AUTOSAR XML (schema 4-2-1)
standard types defined: float32, float64, sint8, sint16, sint32, uint8, uint16, uint32, boolean, dtRef_VOID, Float32, Boolean, UInt8
package /FoundationPkg/FoundationArchitecturePkg
  constant specification iAssistTorque_AssistanceTorque_Init: value-spec={short-label=iAssistTorque_AssistanceTorque_Init, fields=[0 Nm, 0]}
  sender receiver interface iAssistTorque
    data AssistanceTorque: sw-calibration-access=READ-ONLY, type=tAssistTorque, init-value=constant-reference=iAssistTorque_AssistanceTorque_Init
  5 x constant specification:
    iColumnData_ColumnTorque_Init: value-spec={short-label=iColumnData_ColumnTorque_Init, fields=[0 Nm, 0 Nm/s, 0]}
    iColumnData_SteeringPositionLower_Init: value-spec={short-label=iColumnData_SteeringPositionLower_Init, fields=[0 deg, 0, {short-label=tColumnPosition_EQf_Init, fields=[1, 1, 1, 1]}]}
    iColumnData_ColumnVelocity_Init: value-spec={short-label=iColumnData_ColumnVelocity_Init, fields=[0 revs/S, 0 revs/S, 0]}
    iColumnData_SteeringPositionUpper_Init: value-spec={short-label=iColumnData_SteeringPositionUpper_Init, fields=[0 deg, 0, {short-label=tColumnPosition_EQf_Init, fields=[1, 1, 1, 1]}]}
    iColumnData_ColumnPositionLower_Init: value-spec={short-label=iColumnData_ColumnPositionLower_Init, fields=[0 deg, 0, {short-label=tColumnPosition_EQf_Init, fields=[1, 1, 1, 1]}]}
  sender receiver interface iColumnData
    5 x data, all with sw-calibration-access=READ-ONLY:
      ColumnTorque: type=tInputTorque, init-value=constant-reference=iColumnData_ColumnTorque_Init
      SteeringPositionLower: type=tColumnPosition, init-value=constant-reference=iColumnData_SteeringPositionLower_Init
      ColumnVelocity: type=tColumnVelocity, init-value=constant-reference=iColumnData_ColumnVelocity_Init
      SteeringPositionUpper: type=tColumnPosition, init-value=constant-reference=iColumnData_SteeringPositionUpper_Init
      ColumnPositionLower: type=tColumnPosition, init-value=constant-reference=iColumnData_ColumnPositionLower_Init
  client server interface iRack
    4 x operation:
      getMaxPhysicalAssist
        arg maxPhysicalAssist: type=Nm, direction=OUT
      initialisationColumnAngle
        arg pinionAngle: type=Degrees, direction=IN
      translateColumnAngleToRackPosition
        arg pinionAngle: type=Degrees, direction=IN
        arg rackPosition: type=mm, direction=OUT
      translateRackPositionToColumnAngle
        arg rackPosition: type=mm, direction=IN
        arg columnAngle: type=Degrees, direction=OUT
  constant specification iVehicleData_VehicleSpeed_Init: value-spec={short-label=iVehicleData_VehicleSpeed_Init, fields=[0 Kph, 0, 0]}
  constant specification iVehicleData_EstimatedSteeringPosition_Init: value-spec={short-label=iVehicleData_EstimatedSteeringPosition_Init, fields=[0 deg, 0, 0 %]}
  constant specification iVehicleData_YawRate_Init: value-spec={short-label=iVehicleData_YawRate_Init, fields=[0 deg/S, 0]}
  sender receiver interface iVehicleData
    data VehicleSpeed: sw-calibration-access=READ-ONLY, type=tVehicleSpd, init-value=constant-reference=iVehicleData_VehicleSpeed_Init
    data EstimatedSteeringPosition: sw-calibration-access=READ-ONLY, type=tEstimatedSteeringPosition, init-value=constant-reference=iVehicleData_EstimatedSteeringPosition_Init
    data YawRate: sw-calibration-access=READ-ONLY, type=tYawRateData, init-value=constant-reference=iVehicleData_YawRate_Init
  constant specification iFitness_ControllerFitness_Init: value-spec=3
  sender receiver interface iFitness
    data ControllerFitness: sw-calibration-access=READ-ONLY, type=tQualityFactor, init-value=constant-reference=iFitness_ControllerFitness_Init
  constant specification iTuneData_VEHICLE_SPEED_BREAKPOINTS_Init: value-spec=[0.0, 5.0, 10.0, 15.0, 25.0, 35.0, 50.0, 70.0, 90.0, 120.0, 150.0, 190.0]
  constant specification iTuneData_NUM_STEERING_TUNES_Init: value-spec=1
  parameter interface iTuneData
    parameter data prototype VEHICLE_SPEED_BREAKPOINTS: category=ARRAY, sw-addr-method=VehicleTune, sw-calibration-access=READ-WRITE, type=tVspdBkpts_0_0_to_255_0, init-value=constant-reference=iTuneData_VEHICLE_SPEED_BREAKPOINTS_Init
    parameter data prototype NUM_STEERING_TUNES: category=VALUE, sw-addr-method=VehicleTune, sw-calibration-access=READ-WRITE, type=UInt8_1_to_10, init-value=constant-reference=iTuneData_NUM_STEERING_TUNES_Init
  client server interface iRackSizing
    operation getMaxRackTravel
      arg maxRackTravel: type=Degrees, direction=OUT
  client server interface iResetResPositions
    operation resetResLeRiPosition
      arg StraightAheadOffSet: type=tStraightAheadOffset, direction=IN
  constant specification iArbitorResponse_ArbitrationState_Init: value-spec=5
  sender receiver interface iArbitorResponse
    data ArbitrationState: sw-calibration-access=READ-ONLY, type=tArbitrationState, init-value=constant-reference=iArbitorResponse_ArbitrationState_Init
  constant specification iArbitatorRequest_ActivationRequest_Init: value-spec=0
  sender receiver interface iArbitatorRequest
    data ActivationRequest: sw-calibration-access=READ-ONLY, type=tArbitrationState, init-value=constant-reference=iArbitatorRequest_ActivationRequest_Init
  constant specification iResPosition_ResPosnInUse_Init: value-spec={short-label=iResPosition_ResPosnInUse_Init, fields=[0 deg, 0 deg]}
  sender receiver interface iResPosition
    data ResPosnInUse: sw-calibration-access=READ-ONLY, type=tResPosnInUse, init-value=constant-reference=iResPosition_ResPosnInUse_Init
  client server interface iResEnableRequest
    operation setRESEnableRequest
      arg Request: type=Boolean, direction=IN
package /FoundationPkg/FoundationArchitecturePkg/FoundationControllerPkg
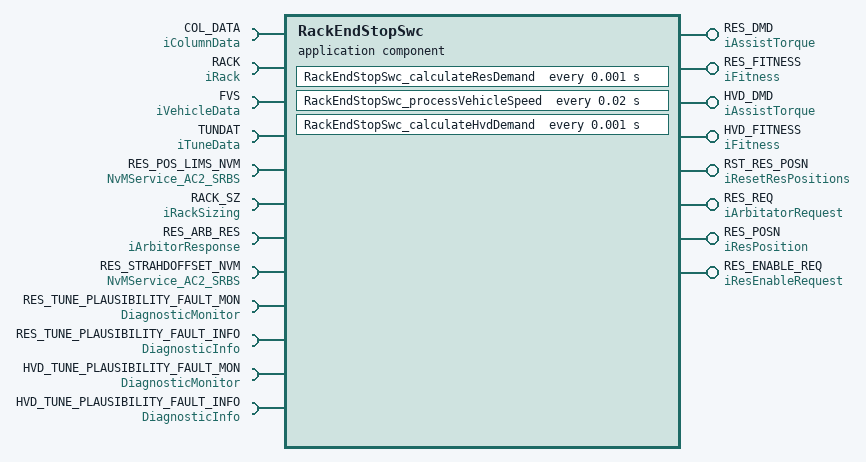
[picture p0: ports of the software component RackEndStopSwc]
  application sw component type RackEndStopSwc
    provide port RES_DMD: nonqueued-sender-com-spec{data-element=AssistanceTorque, init-value=constant-reference=iAssistTorque_AssistanceTorque_Init}, provided-interface=iAssistTorque
    require port COL_DATA: required-interface=iColumnData
      required-com-specs:
        data-element=ColumnTorque, init-value=constant-reference=iColumnData_ColumnTorque_Init
        data-element=SteeringPositionLower, init-value=constant-reference=iColumnData_SteeringPositionLower_Init
        data-element=ColumnVelocity, init-value=constant-reference=iColumnData_ColumnVelocity_Init
        data-element=SteeringPositionUpper, init-value=constant-reference=iColumnData_SteeringPositionUpper_Init
        data-element=ColumnPositionLower, init-value=constant-reference=iColumnData_ColumnPositionLower_Init
    require port RACK: required-interface=iRack
    require port FVS: required-interface=iVehicleData
      required-com-specs:
        data-element=VehicleSpeed, init-value=constant-reference=iVehicleData_VehicleSpeed_Init
        data-element=EstimatedSteeringPosition, init-value=constant-reference=iVehicleData_EstimatedSteeringPosition_Init
        data-element=YawRate, init-value=constant-reference=iVehicleData_YawRate_Init
    provide port RES_FITNESS: nonqueued-sender-com-spec{data-element=ControllerFitness, init-value=constant-reference=iFitness_ControllerFitness_Init}, provided-interface=iFitness
    require port TUNDAT: required-interface=iTuneData
      required-com-specs:
        init-value=constant-reference=iTuneData_VEHICLE_SPEED_BREAKPOINTS_Init, parameter=VEHICLE_SPEED_BREAKPOINTS
        init-value=constant-reference=iTuneData_NUM_STEERING_TUNES_Init, parameter=NUM_STEERING_TUNES
    require port RES_POS_LIMS_NVM: required-interface=NvMService_AC2_SRBS
    provide port HVD_DMD: nonqueued-sender-com-spec{data-element=AssistanceTorque, init-value=constant-reference=iAssistTorque_AssistanceTorque_Init}, provided-interface=iAssistTorque
    provide port HVD_FITNESS: nonqueued-sender-com-spec{data-element=ControllerFitness, init-value=constant-reference=iFitness_ControllerFitness_Init}, provided-interface=iFitness
    require port RACK_SZ: required-interface=iRackSizing
    provide port RST_RES_POSN: server-com-spec{operation=resetResLeRiPosition, queue-length=1}, provided-interface=iResetResPositions
    require port RES_ARB_RES: nonqueued-receiver-com-spec{data-element=ArbitrationState, init-value=constant-reference=iArbitorResponse_ArbitrationState_Init}, required-interface=iArbitorResponse
    provide port RES_REQ: nonqueued-sender-com-spec{data-element=ActivationRequest, init-value=constant-reference=iArbitatorRequest_ActivationRequest_Init}, provided-interface=iArbitatorRequest
    provide port RES_POSN: nonqueued-sender-com-spec{data-element=ResPosnInUse, init-value=constant-reference=iResPosition_ResPosnInUse_Init}, provided-interface=iResPosition
    provide port RES_ENABLE_REQ: server-com-spec{operation=setRESEnableRequest, queue-length=1}, provided-interface=iResEnableRequest
    5 x require port:
      RES_STRAHDOFFSET_NVM: required-interface=NvMService_AC2_SRBS
      RES_TUNE_PLAUSIBILITY_FAULT_MON: required-interface=DiagnosticMonitor
      RES_TUNE_PLAUSIBILITY_FAULT_INFO: required-interface=DiagnosticInfo
      HVD_TUNE_PLAUSIBILITY_FAULT_MON: required-interface=DiagnosticMonitor
      HVD_TUNE_PLAUSIBILITY_FAULT_INFO: required-interface=DiagnosticInfo
    behavior RackEndStopSwc_IB: data-type-mapping=MappingSet, handle-termination-and-restart=NO-SUPPORT
      ar-typed-per-instance-memorys:
        data ResPositionLimitsNvmData: category=STRUCTURE, sw-calibration-access=READ-ONLY, type=tResPositionLimitsNvmData
        data ResStraightAheadOffsetNvmData: category=STRUCTURE, sw-calibration-access=READ-ONLY, type=tResStraightAheadOffsetNvmData
      timing event Event_calculateResDemand: start-on-event=RackEndStopSwc_calculateResDemand, period=0.001
      timing event Event_processVehicleSpeed: start-on-event=RackEndStopSwc_processVehicleSpeed, period=0.02
      init event Event_initialiser_Init: start-on-event=RackEndStopSwc_initialiser
      timing event Event_calculateHvdDemand: start-on-event=RackEndStopSwc_calculateHvdDemand, period=0.001
      operation invoked event Event_resetResLeRiPosition: start-on-event=RackEndStopSwc_resetResLeRiPosition, operation=RST_RES_POSN.resetResLeRiPosition
      operation invoked event Event_setRESEnableRequest: start-on-event=RackEndStopSwc_setRESEnableRequest, operation=RES_ENABLE_REQ.setRESEnableRequest
      explicit-inter-runnable-variables:
        4 x data, all with sw-calibration-access=READ-ONLY:
          triggeringCnt: type=UInt8, init-value=constant-reference=RackEndStopSwc_triggeringCnt_Init
          straightAheadOffset_Value: type=Degrees, init-value=constant-reference=straightAheadOffset_Value_Init
          straightAheadOffset_Qf: type=tQualityFactor, init-value=constant-reference=straightAheadOffset_Qf_Init
          enableResFunctionality: type=Boolean, init-value=constant-reference=RackEndStopSwc_enableResFunctionality_Init  # dedicated to enable/disable the execution of RES functionality
      implicit-inter-runnable-variables:
        9 x data, all with sw-calibration-access=READ-ONLY:
          trqLimit: type=Nm, init-value=constant-reference=RackEndStopSwc_trqLimit_Init
          trqFactor: type=Nm, init-value=constant-reference=RackEndStopSwc_trqFactor_Init
          lwrThres: type=Degrees, init-value=constant-reference=RackEndStopSwc_lwrThres_Init
          denominator: type=Float32, init-value=constant-reference=RackEndStopSwc_denominator_Init
          deadBandLimit: type=Float32, init-value=constant-reference=RackEndStopSwc_deadBandLimit_Init
          linearFactor: type=Float32, init-value=constant-reference=RackEndStopSwc_linearFactor_Init
          maxDampFactor: type=Float32, init-value=constant-reference=RackEndStopSwc_maxDampFactor_Init
          ResTunePlausibilityQf: type=tQualityFactor, init-value=constant-reference=RackEndStopSwc_ResTunePlausibilityQf_Init
          HvdTunePlausibilityQf: type=tQualityFactor, init-value=constant-reference=RackEndStopSwc_HvdTunePlausibilityQf_Init
      per-instance-parameters:
        22 x parameter data prototype:
          RES_POS_OUTWARD_ADAPTION_ENABLED: category=VALUE, sw-addr-method=VehicleTune, sw-calibration-access=READ-WRITE, type=Boolean, init-value=constant-reference=VehicleTune_RES_POS_OUTWARD_ADAPTION_ENABLED_Init
          RES_UPPER_THRESHOLD: category=VALUE, sw-addr-method=VehicleTune, sw-calibration-access=READ-WRITE, type=Degrees_0_0_to_63_0, init-value=constant-reference=VehicleTune_RES_UPPER_THRESHOLD_Init
          RES_VSPD_BKPTS: category=ARRAY, sw-addr-method=VehicleTune, sw-calibration-access=READ-WRITE, type=tResVspdBkpts_0_0_to_255_0, init-value=constant-reference=VehicleTune_RES_VSPD_BKPTS_Init
          RES_LOWER_THRESHOLD_MAP: category=ARRAY, sw-addr-method=VehicleTune, sw-calibration-access=READ-WRITE, type=tResDegreesMap_1_0_to_127_0, init-value=constant-reference=VehicleTune_RES_LOWER_THRESHOLD_MAP_Init
          RES_MAX_TORQUE_FACTOR_MAP: category=ARRAY, sw-addr-method=VehicleTune, sw-calibration-access=READ-WRITE, type=tResPercentMap_0_0_to_1_0, init-value=constant-reference=VehicleTune_RES_MAX_TORQUE_FACTOR_MAP_Init
          RES_TORQUE_LIMIT_MAP: category=ARRAY, sw-addr-method=VehicleTune, sw-calibration-access=READ-WRITE, type=tResPercentMap_0_0_to_1_0, init-value=constant-reference=VehicleTune_RES_TORQUE_LIMIT_MAP_Init
          RES_MAX_OUTWARD_ADAPTATION_THRESHOLD: category=VALUE, sw-addr-method=VehicleTune, sw-calibration-access=READ-WRITE, type=Degrees_0_0_to_720_0, init-value=constant-reference=VehicleTune_RES_MAX_OUTWARD_ADAPTATION_THRESHOLD_Init
          HVD_DEAD_BAND_LIMIT_MAP: category=ARRAY, sw-addr-method=VehicleTune, sw-calibration-access=READ-WRITE, type=tHvdDeadBandLimitMap_2_5_to_8_0, init-value=constant-reference=VehicleTune_HVD_DEAD_BAND_LIMIT_MAP_Init
          HVD_LINEAR_FACTOR_MAP: category=ARRAY, sw-addr-method=VehicleTune, sw-calibration-access=READ-WRITE, type=tHvdLinearFactorMap_0_0_to_2_0, init-value=constant-reference=VehicleTune_HVD_LINEAR_FACTOR_MAP_Init
          HVD_MAX_DAMP_LIMIT_MAP: category=ARRAY, sw-addr-method=VehicleTune, sw-calibration-access=READ-WRITE, type=tHvdMaxDampLimitMap_0_0_to_1_0, init-value=constant-reference=VehicleTune_HVD_MAX_DAMP_LIMIT_MAP_Init  # Column velocity threshold for RES damping
          RES_TOLERANCE_MARGIN: category=VALUE, sw-addr-method=VehicleTune, sw-calibration-access=READ-WRITE, type=Degrees_0_0_to_50_0, init-value=constant-reference=VehicleTune_RES_TOLERANCE_MARGIN_Init
          RES_DEAC_TQ_RAMP_RATE: category=VALUE, sw-addr-method=VehicleTune, sw-calibration-access=READ-WRITE, type=NmPerSec_50_0_to_255000_0, init-value=constant-reference=VehicleTune_RES_DEAC_TQ_RAMP_RATE_Init
          HVD_MIN_COL_V_THD: category=VALUE, sw-addr-method=VehicleTune, sw-calibration-access=READ-WRITE, type=RevsPerSec_0_0_to_8_0, init-value=constant-reference=VehicleTune_HVD_MIN_COL_V_THD_Init
          RES_POSN_DAMP_BKPTS: category=ARRAY, sw-addr-method=VehicleTune, sw-calibration-access=READ-WRITE, type=tResPosBpts_0_0_to_127_0, init-value=constant-reference=VehicleTune_RES_POSN_DAMP_BKPTS_Init  # RES damping breakpoints
          RES_STEERING_TO_END_DAMPG_MAP: category=ARRAY, sw-addr-method=VehicleTune, sw-calibration-access=READ-WRITE, type=tResDmpgMap_0_0_to_1_0, init-value=constant-reference=VehicleTune_RES_STEERING_TO_END_DAMPG_MAP_Init  # Damping torque towards rack ends
          RES_LOWER_DAMPG_THRESHOLD: category=VALUE, sw-addr-method=VehicleTune, sw-calibration-access=READ-WRITE, type=Degrees_1_0_to_127_0, init-value=constant-reference=VehicleTune_RES_LOWER_DAMPG_THRESHOLD_Init  # Position threshold for RES damping
          RES_MAX_COLUMN_VELOCITY: category=VALUE, sw-addr-method=VehicleTune, sw-calibration-access=READ-WRITE, type=RevsPerSec_0_0_to_8_0, init-value=constant-reference=VehicleTune_RES_MAX_COLUMN_VELOCITY_Init
          RES_NOT_LEARNED_TQ_MULTIPLIER: category=VALUE, sw-addr-method=VehicleTune, sw-calibration-access=READ-WRITE, type=Percent_0_0_to_1_0, init-value=constant-reference=VehicleTune_RES_NOT_LEARNED_TQ_MULTIPLIER_Init  # Gain value of torque demand
          RES_STEERING_TO_CENTER_DAMPG_MAP: category=ARRAY, sw-addr-method=VehicleTune, sw-calibration-access=READ-WRITE, type=tResDmpgMap_0_0_to_1_0, init-value=constant-reference=VehicleTune_RES_STEERING_TO_CENTER_DAMPG_MAP_Init  # Damping torque towards rack center
          RES_NOT_LEARNED_DAMPG_MULTIPLIER: category=VALUE, sw-addr-method=VehicleTune, sw-calibration-access=READ-WRITE, type=Percent_0_0_to_1_0, init-value=constant-reference=VehicleTune_RES_NOT_LEARNED_DAMPG_MULTIPLIER_Init  # Gain value of damping
          ResPositionLimitsNvmData_DEFAULT_VALUE: category=RECORD, type=tResPositionLimitsNvmData, init-value=constant-reference=RackEndStopSwc_ResPositionLimitsNvmData_Init
          ResStraightAheadOffsetNvmData_DEFAULT_VALUE: category=RECORD, type=tResStraightAheadOffsetNvmData, init-value=constant-reference=RackEndStopSwc_ResStraightAheadOffsetNvmData_Init
      6 x runnable:
        RackEndStopSwc_calculateResDemand: symbol=RackEndStop_calculateResDemand
          data-read-access:
            4 x access:
              R_COL_DATA_ColumnVelocity: accessed-variable=COL_DATA.ColumnVelocity
              R_COL_DATA_ColumnPositionLower: accessed-variable=COL_DATA.ColumnPositionLower
              R_COL_DATA_SteeringPositionLower: accessed-variable=COL_DATA.SteeringPositionLower
              R_RES_ARB_RES_ArbitrationState: accessed-variable=RES_ARB_RES.ArbitrationState
          data-write-access:
            4 x access:
              W_RES_DMD_AssistanceTorque: accessed-variable=RES_DMD.AssistanceTorque
              W_RES_FITNESS_ControllerFitness: accessed-variable=RES_FITNESS.ControllerFitness
              W_RES_REQ_ActivationRequest: accessed-variable=RES_REQ.ActivationRequest
              W_RES_POSN_ResPosnInUse: accessed-variable=RES_POSN.ResPosnInUse
          12 x parameter access:
            RES_MAX_OUTWARD_ADAPTATION_THRESHOLD: accessed-parameter=RES_MAX_OUTWARD_ADAPTATION_THRESHOLD
            RES_POS_OUTWARD_ADAPTION_ENABLED: accessed-parameter=RES_POS_OUTWARD_ADAPTION_ENABLED
            RES_UPPER_THRESHOLD: accessed-parameter=RES_UPPER_THRESHOLD
            RES_TOLERANCE_MARGIN: accessed-parameter=RES_TOLERANCE_MARGIN
            RES_DEAC_TQ_RAMP_RATE: accessed-parameter=RES_DEAC_TQ_RAMP_RATE
            RES_POSN_DAMP_BKPTS: accessed-parameter=RES_POSN_DAMP_BKPTS
            RES_STEERING_TO_CENTER_DAMPG_MAP: accessed-parameter=RES_STEERING_TO_CENTER_DAMPG_MAP
            RES_STEERING_TO_END_DAMPG_MAP: accessed-parameter=RES_STEERING_TO_END_DAMPG_MAP
            RES_LOWER_DAMPG_THRESHOLD: accessed-parameter=RES_LOWER_DAMPG_THRESHOLD
            RES_MAX_COLUMN_VELOCITY: accessed-parameter=RES_MAX_COLUMN_VELOCITY
            RES_NOT_LEARNED_DAMPG_MULTIPLIER: accessed-parameter=RES_NOT_LEARNED_DAMPG_MULTIPLIER
            RES_NOT_LEARNED_TQ_MULTIPLIER: accessed-parameter=RES_NOT_LEARNED_TQ_MULTIPLIER
          read-local-variables:
            9 x access:
              RV_denominator: accessed-variable=denominator
              RV_lwrThres: accessed-variable=lwrThres
              RV_trqFactor: accessed-variable=trqFactor
              RV_trqLimit: accessed-variable=trqLimit
              RV_triggeringCnt: accessed-variable=triggeringCnt
              RV_straightAheadOffset_Value: accessed-variable=straightAheadOffset_Value
              RV_straightAheadOffset_Qf: accessed-variable=straightAheadOffset_Qf
              RV_ResTunePlausibilityQf: accessed-variable=ResTunePlausibilityQf
              RV_enableResFunctionality: accessed-variable=enableResFunctionality
          sync call Call_RES_POS_LIMS_NVM_SetRamBlockStatus: operation=RES_POS_LIMS_NVM.SetRamBlockStatus, timeout=0
          sync call Call_RACK_SZ_getMaxRackTravel: operation=RACK_SZ.getMaxRackTravel, timeout=0
          sync call Call_RACK_getMaxPhysicalAssist: operation=RACK.getMaxPhysicalAssist, timeout=0
        RackEndStopSwc_processVehicleSpeed: symbol=RackEndStop_processVehicleSpeed
          data-read-access:
            access R_FVS_VehicleSpeed: accessed-variable=FVS.VehicleSpeed
            access R_COL_DATA_ColumnPositionLower: accessed-variable=COL_DATA.ColumnPositionLower
          8 x parameter access:
            RES_LOWER_THRESHOLD_MAP: accessed-parameter=RES_LOWER_THRESHOLD_MAP
            RES_MAX_TORQUE_FACTOR_MAP: accessed-parameter=RES_MAX_TORQUE_FACTOR_MAP
            RES_TORQUE_LIMIT_MAP: accessed-parameter=RES_TORQUE_LIMIT_MAP
            RES_VSPD_BKPTS: accessed-parameter=RES_VSPD_BKPTS
            HVD_DEAD_BAND_LIMIT_MAP: accessed-parameter=HVD_DEAD_BAND_LIMIT_MAP
            HVD_LINEAR_FACTOR_MAP: accessed-parameter=HVD_LINEAR_FACTOR_MAP
            HVD_MAX_DAMP_LIMIT_MAP: accessed-parameter=HVD_MAX_DAMP_LIMIT_MAP
            VEHICLE_SPEED_BREAKPOINTS: accessed-parameter=TUNDAT.VEHICLE_SPEED_BREAKPOINTS
          read-local-variables:
            access RV_ResTunePlausibilityQf: accessed-variable=ResTunePlausibilityQf
            access RV_HvdTunePlausibilityQf: accessed-variable=HvdTunePlausibilityQf
            access RV_enableResFunctionality: accessed-variable=enableResFunctionality
          sync call Call_RACK_getMaxPhysicalAssist: operation=RACK.getMaxPhysicalAssist, timeout=0
          written-local-variables:
            7 x access:
              WV_trqLimit: accessed-variable=trqLimit
              WV_trqFactor: accessed-variable=trqFactor
              WV_lwrThres: accessed-variable=lwrThres
              WV_denominator: accessed-variable=denominator
              WV_deadBandLimit: accessed-variable=deadBandLimit
              WV_linearFactor: accessed-variable=linearFactor
              WV_maxDampFactor: accessed-variable=maxDampFactor
        RackEndStopSwc_initialiser: symbol=RackEndStop_initialiser
          5 x parameter access:
            RES_VSPD_BKPTS: accessed-parameter=RES_VSPD_BKPTS
            RES_LOWER_THRESHOLD_MAP: accessed-parameter=RES_LOWER_THRESHOLD_MAP
            HVD_DEAD_BAND_LIMIT_MAP: accessed-parameter=HVD_DEAD_BAND_LIMIT_MAP
            VEHICLE_SPEED_BREAKPOINTS: accessed-parameter=TUNDAT.VEHICLE_SPEED_BREAKPOINTS
            HVD_MIN_COL_V_THD: accessed-parameter=HVD_MIN_COL_V_THD
          8 x sync call, all with timeout=0:
            Call_HVD_TUNE_PLAUSIBILITY_FAULT_SetEventStatus: operation=HVD_TUNE_PLAUSIBILITY_FAULT_MON.SetEventStatus
            Call_HVD_TUNE_PLAUSIBILITY_FAULT_ResetEventStatus: operation=HVD_TUNE_PLAUSIBILITY_FAULT_MON.ResetEventDebounceStatus
            Call_HVD_TUNE_PLAUSIBILITY_FAULT_GetEventStatus: operation=HVD_TUNE_PLAUSIBILITY_FAULT_INFO.GetEventStatus
            Call_HVD_TUNE_PLAUSIBILITY_FAULT_GetEventFailed: operation=HVD_TUNE_PLAUSIBILITY_FAULT_INFO.GetEventFailed
            Call_RES_TUNE_PLAUSIBILITY_FAULT_SetEventStatus: operation=RES_TUNE_PLAUSIBILITY_FAULT_MON.SetEventStatus
            Call_RES_TUNE_PLAUSIBILITY_FAULT_ResetEventStatus: operation=RES_TUNE_PLAUSIBILITY_FAULT_MON.ResetEventDebounceStatus
            Call_RES_TUNE_PLAUSIBILITY_FAULT_GetEventStatus: operation=RES_TUNE_PLAUSIBILITY_FAULT_INFO.GetEventStatus
            Call_RES_TUNE_PLAUSIBILITY_FAULT_GetEventFailed: operation=RES_TUNE_PLAUSIBILITY_FAULT_INFO.GetEventFailed
          written-local-variables:
            access WV_ResTunePlausibilityQf: accessed-variable=ResTunePlausibilityQf
            access WV_HvdTunePlausibilityQf: accessed-variable=HvdTunePlausibilityQf
        RackEndStopSwc_calculateHvdDemand: symbol=RackEndStop_calculateHvdDemand
          data-read-access:
            access R_COL_DATA_ColumnVelocity: accessed-variable=COL_DATA.ColumnVelocity
            access R_FVS_VehicleSpeed: accessed-variable=FVS.VehicleSpeed
          data-write-access:
            access W_HVD_DMD_AssistanceTorque: accessed-variable=HVD_DMD.AssistanceTorque
            access W_HVD_FITNESS_ControllerFitness: accessed-variable=HVD_FITNESS.ControllerFitness
          read-local-variables:
            4 x access:
              RV_linearFactor: accessed-variable=linearFactor
              RV_maxDampFactor: accessed-variable=maxDampFactor
              RV_deadBandLimit: accessed-variable=deadBandLimit
              RV_HvdTunePlausibilityQf: accessed-variable=HvdTunePlausibilityQf
          sync call Call_RACK_getMaxPhysicalAssist: operation=RACK.getMaxPhysicalAssist, timeout=0
        RackEndStopSwc_resetResLeRiPosition: symbol=RackEndStop_resetResLeRiPosition  # This runnable is dedicated to reset the RES positions (Left&right) once after straight ahead calibration is done successfully by the software component which is dedicated to perform the straight ahead calibration. In case this runnable is triggered, it just resets the NVM values Left position & right position with the default values stored as a calibration parameters.
          sync call Call_RES_STRAHDOFFSET_NVM_SetRamBlockStatus: operation=RES_STRAHDOFFSET_NVM.SetRamBlockStatus, timeout=0
          written-local-variables:
            access WV_straightAheadOffset_Value: accessed-variable=straightAheadOffset_Value
            access WV_straightAheadOffset_Qf: accessed-variable=straightAheadOffset_Qf
            access WV_triggeringCnt: accessed-variable=triggeringCnt
        RackEndStopSwc_setRESEnableRequest: symbol=RackEndStop_setRESEnableRequest  # This service is dedicated to store the Feature enabling/disabling request in NVM. As the SW component doesn't know about the system states, therefore the storing of feature activation status can be done directly in the service. For this purpose the Rte_Pim interface can be called directly inside the service to store the feature enabling disabling request in RAM block. TRUE indicates Feature Enable FALSE indicates Feature Disable
          written-local-variables:
            access WV_enableResFunctionality: accessed-variable=enableResFunctionality
      6 x swc service dependency:
        SwcNv_ResPositionLimitsNvmData: assigned-ports=role-based-port-assignment={port-prototype=RES_POS_LIMS_NVM, role=ResPositionLimitsNvmData}
          assigned-datas:
            role=ramBlock, used-data-element=ResPositionLimitsNvmData
            role=defaultValue, used-parameter-element=ResPositionLimitsNvmData_DEFAULT_VALUE
          service-needs:
            nv block needs SwcNv_ResPositionLimitsNvmData: calc-ram-block-crc=true, check-static-block-id=false, n-rom-blocks=1, ram-block-status-control=NV-RAM-MANAGER, readonly=false, reliability=ERROR-DETECTION, resistant-to-changed-sw=false, restore-at-start=true, store-at-shutdown=true, store-cyclic=false, store-emergency=false, store-immediate=false, use-auto-validation-at-shut-down=false, use-crc-comp-mechanism=true, write-only-once=false, write-verification=false
        SwcNv_ResStraightAheadOffsetNvmData: assigned-ports=role-based-port-assignment={port-prototype=RES_STRAHDOFFSET_NVM, role=ResStraightAheadOffsetNvmData}
          assigned-datas:
            role=ramBlock, used-data-element=ResStraightAheadOffsetNvmData
            role=defaultValue, used-parameter-element=ResStraightAheadOffsetNvmData_DEFAULT_VALUE
          service-needs:
            nv block needs SwcNv_ResStraightAheadOffsetNvmData: calc-ram-block-crc=true, check-static-block-id=false, n-rom-blocks=1, ram-block-status-control=NV-RAM-MANAGER, readonly=false, reliability=ERROR-DETECTION, resistant-to-changed-sw=false, restore-at-start=true, store-at-shutdown=false, store-cyclic=false, store-emergency=false, store-immediate=true, use-auto-validation-at-shut-down=false, use-crc-comp-mechanism=true, write-only-once=false, write-verification=false
        Monitor_RES_TUNE_PLAUSIBILITY_FAULT: assigned-ports=role-based-port-assignment={port-prototype=RES_TUNE_PLAUSIBILITY_FAULT_MON, role=DiagnosticMonitor}
          service-needs:
            diagnostic event needs EventNeed_RES_TUNE_PLAUSIBILITY_FAULT
        Info_RES_TUNE_PLAUSIBILITY_FAULT: assigned-ports=role-based-port-assignment={port-prototype=RES_TUNE_PLAUSIBILITY_FAULT_INFO, role=DiagnosticInfo}
          service-needs:
            diagnostic event info needs InfoNeed_RES_TUNE_PLAUSIBILITY_FAULT
        Monitor_HVD_TUNE_PLAUSIBILITY_FAULT: assigned-ports=role-based-port-assignment={port-prototype=HVD_TUNE_PLAUSIBILITY_FAULT_MON, role=DiagnosticMonitor}
          service-needs:
            diagnostic event needs EventNeed_HVD_TUNE_PLAUSIBILITY_FAULT
        Info_HVD_TUNE_PLAUSIBILITY_FAULT: assigned-ports=role-based-port-assignment={port-prototype=HVD_TUNE_PLAUSIBILITY_FAULT_INFO, role=DiagnosticInfo}
          service-needs:
            diagnostic event info needs InfoNeed_HVD_TUNE_PLAUSIBILITY_FAULT
  impl type tResPositionLimitsNvmData: category=STRUCTURE
    element LeftPosition: implementation-data-type=Degrees
    element RightPosition: implementation-data-type=Degrees
  impl type tResStraightAheadOffsetNvmData: category=STRUCTURE
    element StraightAheadOffset: implementation-data-type=tStraightAheadOffset
  33 x constant specification:
    RackEndStopSwc_triggeringCnt_Init: value-spec=0
    RackEndStopSwc_enableResFunctionality_Init: value-spec=1
    RackEndStopSwc_trqLimit_Init: value-spec=0.0
    RackEndStopSwc_trqFactor_Init: value-spec=0.0
    RackEndStopSwc_lwrThres_Init: value-spec=0.0
    RackEndStopSwc_denominator_Init: value-spec=0.0
    RackEndStopSwc_deadBandLimit_Init: value-spec=0.0
    RackEndStopSwc_linearFactor_Init: value-spec=0.0
    RackEndStopSwc_maxDampFactor_Init: value-spec=0.0
    RackEndStopSwc_ResTunePlausibilityQf_Init: value-spec=0
    RackEndStopSwc_HvdTunePlausibilityQf_Init: value-spec=0
    VehicleTune_RES_POS_OUTWARD_ADAPTION_ENABLED_Init: value-spec=1
    VehicleTune_RES_UPPER_THRESHOLD_Init: value-spec=7.0
    VehicleTune_RES_VSPD_BKPTS_Init: value-spec=[0.0, 2.0, 12.0, 24.0]
    VehicleTune_RES_LOWER_THRESHOLD_MAP_Init: value-spec=[45.0, 42.0, 40.0, 40.0]
    VehicleTune_RES_MAX_TORQUE_FACTOR_MAP_Init: value-spec=[1.0, 1.0, 1.0, 1.0]
    VehicleTune_RES_TORQUE_LIMIT_MAP_Init: value-spec=[1.0, 1.0, 1.0, 1.0]
    VehicleTune_RES_MAX_OUTWARD_ADAPTATION_THRESHOLD_Init: value-spec=720.0
    VehicleTune_HVD_DEAD_BAND_LIMIT_MAP_Init: value-spec=[2.7, 2.7, 2.7, 2.7, 2.7, 2.7, 2.7, 2.7, 2.7, 2.5, 2.5, 2.5]
    VehicleTune_HVD_LINEAR_FACTOR_MAP_Init: value-spec=[2.0, 2.0, 2.0, 2.0, 2.0, 2.0, 2.0, 2.0, 2.0, 1.3, 0.7, 0.0]
    VehicleTune_HVD_MAX_DAMP_LIMIT_MAP_Init: value-spec=[1.0, 1.0, 1.0, 1.0, 1.0, 0.77, 0.46, 0.15, 0.0, 0.0, 0.0, 0.0]
    VehicleTune_RES_TOLERANCE_MARGIN_Init: value-spec=10.0
    VehicleTune_RES_DEAC_TQ_RAMP_RATE_Init: value-spec=70.0
    VehicleTune_HVD_MIN_COL_V_THD_Init: value-spec=1.0
    VehicleTune_RES_POSN_DAMP_BKPTS_Init: value-spec=[0.0, 10.0, 20.0, 30.0, 40.0]
    VehicleTune_RES_STEERING_TO_END_DAMPG_MAP_Init: value-spec=[0.0, 0.25, 0.5, 0.75, 1.0]
    VehicleTune_RES_LOWER_DAMPG_THRESHOLD_Init: value-spec=40.0
    VehicleTune_RES_MAX_COLUMN_VELOCITY_Init: value-spec=2.5
    VehicleTune_RES_NOT_LEARNED_TQ_MULTIPLIER_Init: value-spec=0.0
    VehicleTune_RES_STEERING_TO_CENTER_DAMPG_MAP_Init: value-spec=[0.0, 0.25, 0.5, 0.75, 1.0]
    VehicleTune_RES_NOT_LEARNED_DAMPG_MULTIPLIER_Init: value-spec=0.0
    RackEndStopSwc_ResPositionLimitsNvmData_Init: value-spec={short-label=RackEndStopSwc_ResPositionLimitsNvmData_Init, fields=[0.0, 0.0]}
    RackEndStopSwc_ResStraightAheadOffsetNvmData_Init: value-spec={short-label=RackEndStopSwc_ResStraightAheadOffsetNvmData_Init, fields={short-label=ResStraightAheadOffsetNvmData_StraightAheadOffset_Init, fields=[0.0, 0]}}
package /FoundationPkg/FoundationArchitecturePkg/FoundationControllerPkg/ApplicationTypesPkg
  application record data type tResPositionLimitsNvmData: category=STRUCTURE  # NVM data store for RES values.
    application record element LeftPosition: category=VALUE, type=Degrees_0_0_to_720_0
    application record element RightPosition: category=VALUE, type=Degrees_0_0_to_720_0
  application record data type tResStraightAheadOffsetNvmData: category=STRUCTURE
    application record element StraightAheadOffset: category=STRUCTURE, type=tStraightAheadOffset
package /FoundationPkg/FoundationArchitecturePkg/FoundationTypes
  unit Nm_Unit: display-name=Nm
  impl type Nm: implementation-data-type=Float32
  compu method tQualityFactor_Compu: 0=QF_UNINITIALIZED, 0=QF_UNINITIALISED, 1=QF_UNAVAILABLE, 2=QF_DEGRADED, 3=QF_FULL
  impl type tQualityFactor: category=VALUE, base-type=sint32, compu-method=tQualityFactor_Compu
  impl type tAssistTorque: category=STRUCTURE
    element Value: implementation-data-type=Nm
    element Qf: implementation-data-type=tQualityFactor
  unit NmPerSec_Unit: display-name=Nm/s
  impl type NmPerSec: implementation-data-type=Float32
  impl type tInputTorque: category=STRUCTURE
    element Value: implementation-data-type=Nm
    element Derivative: implementation-data-type=NmPerSec
    element Qf: implementation-data-type=tQualityFactor
  unit Degrees_Unit: display-name=deg
  impl type Degrees: implementation-data-type=Float32
  impl type tExtendedQf: category=STRUCTURE
    4 x element, all with category=TYPE_REFERENCE, implementation-data-type=Boolean:
      IntegrityDegraded
      ResolutionDegraded
      LossOfRedundancy
      Defaulted
  impl type tColumnPosition: category=STRUCTURE
    element Value: implementation-data-type=Degrees
    element Qf: implementation-data-type=tQualityFactor
    element EQf: implementation-data-type=tExtendedQf
  unit RevsPerSec_Unit: display-name=revs/S
  impl type RevsPerSec: implementation-data-type=Float32
  impl type tColumnVelocity: category=STRUCTURE
    element Filtered: implementation-data-type=RevsPerSec
    element Unfiltered: implementation-data-type=RevsPerSec
    element Qf: implementation-data-type=tQualityFactor
  unit mm_Unit: display-name=mm
  impl type mm: implementation-data-type=Float32
  unit Kph_Unit: display-name=Kph
  impl type Kph: implementation-data-type=Float32
  impl type tVehicleSpd: category=STRUCTURE
    element Filtered: implementation-data-type=Kph
    element Moving: implementation-data-type=Boolean
    element Qf: implementation-data-type=tQualityFactor
  unit Percent_Unit: display-name=%
  impl type Percent: implementation-data-type=Float32
  impl type tEstimatedSteeringPosition: category=STRUCTURE
    element Value: implementation-data-type=Degrees
    element Qf: implementation-data-type=tQualityFactor
    element Confidence: implementation-data-type=Percent
  unit DegreesPerSec_Unit: display-name=deg/S
  impl type DegreesPerSec: implementation-data-type=Float32
  impl type tYawRateData: category=STRUCTURE
    element Value: implementation-data-type=DegreesPerSec
    element Qf: implementation-data-type=tQualityFactor
  impl type tVspdBkpts: category=ARRAY
    element Element: array-size=12, array-size-semantics=FIXED-SIZE, implementation-data-type=Float32
  impl type tStraightAheadOffset: category=STRUCTURE
    element Value: implementation-data-type=Degrees
    element Qf: implementation-data-type=tQualityFactor
  compu method tArbitrationState_Compu: 0=ARB_PASSIVE, 1=ARB_REQ_ACT, 2=ARB_RAMP_IN, 3=ARB_ACTIVE, 4=ARB_RAMP_OUT, 5=ARB_LOCKED, 99=ARB_READY
  impl type tArbitrationState: category=VALUE, base-type=sint32, compu-method=tArbitrationState_Compu
  impl type tResPosnInUse: category=STRUCTURE
    element ResPosnNegInUse: implementation-data-type=Degrees
    element ResPosnPosInUse: implementation-data-type=Degrees
  constant specification straightAheadOffset_Value_Init: value-spec=0.0
  constant specification straightAheadOffset_Qf_Init: value-spec=0
  impl type tResVspdBkpts: category=ARRAY
    element Element: array-size=4, array-size-semantics=FIXED-SIZE, implementation-data-type=Kph
  impl type tResDegreesMap: category=ARRAY
    element Element: array-size=4, array-size-semantics=FIXED-SIZE, implementation-data-type=Degrees
  impl type tResPercentMap: category=ARRAY
    element Element: array-size=4, array-size-semantics=FIXED-SIZE, implementation-data-type=Percent
  impl type tHvdDeadBandLimitMap: category=ARRAY
    element Element: array-size=12, array-size-semantics=FIXED-SIZE, implementation-data-type=DegreesPerSec
  unit DegreesPerSec_1_Unit: display-name=1/deg/S
  impl type DegreesPerSec_1: implementation-data-type=Float32
  impl type tHvdLinearFactorMap: category=ARRAY
    element Element: array-size=12, array-size-semantics=FIXED-SIZE, implementation-data-type=DegreesPerSec_1
  impl type tHvdMaxDampLimitMap: category=ARRAY
    element Element: array-size=12, array-size-semantics=FIXED-SIZE, implementation-data-type=Float32
  impl type tResPosBpts: category=ARRAY
    element Element: array-size=5, array-size-semantics=FIXED-SIZE, implementation-data-type=Degrees
  impl type tResDmpgMap: category=ARRAY
    element Element: array-size=5, array-size-semantics=FIXED-SIZE, implementation-data-type=Percent
package /FoundationPkg/FoundationArchitecturePkg/FoundationTypes/ApplicationTypesPkg
  app type Nm_n255_0_to_255_0: category=VALUE, compu {phys=raw for raw -255..255; unit Nm}, range phys -255..255, unit=Nm
  app type Float32: category=VALUE
  app type tQualityFactor: category=VALUE, base-type=sint32, compu-method=tQualityFactor_Compu  # Describes the quality of an input signal.
  application record data type tAssistTorque: category=STRUCTURE
    application record element Value: category=VALUE, type=Nm_n255_0_to_255_0
    application record element Qf: category=VALUE, type=tQualityFactor
  app type Nm: category=VALUE, compu {phys=raw for raw -10..10; unit Nm}, range phys -10..10, unit=Nm
  app type NmPerSec: category=VALUE, compu {phys=raw for raw -2048..2048; unit Nm/s}, range phys -2048..2048, unit=Nm/s  # Rate of change of torque
  application record data type tInputTorque: category=STRUCTURE
    application record element Value: category=VALUE, type=Nm
    application record element Derivative: category=VALUE, type=NmPerSec
    application record element Qf: category=VALUE, type=tQualityFactor
  app type Degrees_n720_0_to_720_0: category=VALUE, compu {phys=raw for raw -720..720; unit deg}, range phys -720..720, unit=deg
  app type Boolean: category=VALUE
  application record data type tExtendedQf: category=STRUCTURE  # Extended quality information for a signal, used in conjunction with tQualityFactor. Legal combinations are: Qf = QF_UNINITIALISED, QF_UNINITIALIZED: eQf should be ignored. Qf = QF_UNAVAILABLE: eQf should be ignored. Qf = QF_DEGRADED: eQf - may have any combination of LossOfRedundancy, LossOfIntegrity, ResolutionDegraded or Defaulted set to True. Qf = QF_FULL: eQf may only have LossOfRedundancy set to True.
    4 x application record element, all with category=VALUE, type=Boolean:
      IntegrityDegraded
      ResolutionDegraded
      LossOfRedundancy
      Defaulted
  application record data type tColumnPosition: category=STRUCTURE  # Measument of the Column position in degrees with range -720 - +720.
    application record element Value: category=VALUE, type=Degrees_n720_0_to_720_0
    application record element Qf: category=VALUE, type=tQualityFactor
    application record element EQf: category=STRUCTURE, type=tExtendedQf
  app type Degrees: category=VALUE, compu {phys=raw for raw -INF..INF; unit deg}, unit=deg
  app type RevsPerSec: category=VALUE, compu {phys=raw for raw -INF..INF; unit revs/S}, unit=revs/S
  application record data type tColumnVelocity: category=STRUCTURE
    application record element Filtered: category=VALUE, type=RevsPerSec
    application record element Unfiltered: category=VALUE, type=RevsPerSec
    application record element Qf: category=VALUE, type=tQualityFactor
  app type mm: category=VALUE, compu {phys=raw for raw -INF..INF; unit mm}, unit=mm
  app type Kph_0_to_400: category=VALUE, compu {phys=raw for raw 0..400; unit Kph}, range phys 0..400, unit=Kph
  application record data type tVehicleSpd: category=STRUCTURE
    application record element Filtered: category=VALUE, type=Kph_0_to_400
    application record element Moving: category=VALUE, type=Boolean
    application record element Qf: category=VALUE, type=tQualityFactor
  app type Kph: category=VALUE, compu {phys=raw for raw -INF..INF; unit Kph}, unit=Kph
  app type Percent: category=VALUE, compu {phys=raw for raw 0..100; unit %}, range phys 0..100, unit=%
  application record data type tEstimatedSteeringPosition: category=STRUCTURE
    application record element Value: category=VALUE, type=Degrees_n720_0_to_720_0
    application record element Qf: category=VALUE, type=tQualityFactor
    application record element Confidence: category=VALUE, type=Percent
  app type DegreesPerSec: category=VALUE, compu {phys=raw for raw -INF..INF; unit deg/S}, unit=deg/S
  application record data type tYawRateData: category=STRUCTURE
    application record element Value: category=VALUE, type=DegreesPerSec
    application record element Qf: category=VALUE, type=tQualityFactor
  app type Float32_0_0_to_255_0: category=VALUE, range phys 0..255
  application array data type tVspdBkpts_0_0_to_255_0: category=ARRAY
    element Element: category=VALUE, type=Float32_0_0_to_255_0, array-size-semantics=FIXED-SIZE, max-number-of-elements=12
  app type UInt8_1_to_10: category=VALUE, range phys 1..10
  application record data type tStraightAheadOffset: category=STRUCTURE
    application record element Value: category=VALUE, type=Degrees
    application record element Qf: category=VALUE, type=tQualityFactor
  app type tArbitrationState: category=VALUE, base-type=sint32, compu-method=tArbitrationState_Compu
  application record data type tResPosnInUse: category=STRUCTURE
    application record element ResPosnNegInUse: category=VALUE, type=Degrees
    application record element ResPosnPosInUse: category=VALUE, type=Degrees
  4 x app type, all with category=VALUE:
    Degrees_0_0_to_720_0: compu {phys=raw for raw 0..720; unit deg}, range phys 0..720, unit=deg
    UInt8
    Degrees_0_0_to_63_0: compu {phys=raw for raw 0..63; unit deg}, range phys 0..63, unit=deg
    Kph_0_0_to_255_0: compu {phys=raw for raw 0..255; unit Kph}, range phys 0..255, unit=Kph
  application array data type tResVspdBkpts_0_0_to_255_0: category=ARRAY
    element Element: category=VALUE, type=Kph_0_0_to_255_0, array-size-semantics=FIXED-SIZE, max-number-of-elements=4
  app type Degrees_1_0_to_127_0: category=VALUE, compu {phys=raw for raw 1..127; unit deg}, range phys 1..127, unit=deg
  application array data type tResDegreesMap_1_0_to_127_0: category=ARRAY
    element Element: category=VALUE, type=Degrees_1_0_to_127_0, array-size-semantics=FIXED-SIZE, max-number-of-elements=4
  app type Percent_0_0_to_1_0: category=VALUE, compu {phys=raw for raw 0..1; unit %}, range phys 0..1, unit=%
  application array data type tResPercentMap_0_0_to_1_0: category=ARRAY
    element Element: category=VALUE, type=Percent_0_0_to_1_0, array-size-semantics=FIXED-SIZE, max-number-of-elements=4
  app type DegreesPerSec_2_5_to_8_0: category=VALUE, compu {phys=raw for raw 2.5..8; unit deg/S}, range phys 2.5..8, unit=deg/S
  application array data type tHvdDeadBandLimitMap_2_5_to_8_0: category=ARRAY
    element Element: category=VALUE, type=DegreesPerSec_2_5_to_8_0, array-size-semantics=FIXED-SIZE, max-number-of-elements=12
  app type DegreesPerSec_1_0_0_to_2_0: category=VALUE, compu {phys=raw for raw 0..2; unit 1/deg/S}, range phys 0..2, unit=1/deg/S
  application array data type tHvdLinearFactorMap_0_0_to_2_0: category=ARRAY
    element Element: category=VALUE, type=DegreesPerSec_1_0_0_to_2_0, array-size-semantics=FIXED-SIZE, max-number-of-elements=12
  app type DegreesPerSec_1: category=VALUE, compu {phys=raw for raw 0..0.2; unit 1/deg/S}, range phys 0..0.2, unit=1/deg/S
  app type Float32_0_0_to_1_0: category=VALUE, range phys 0..1
  application array data type tHvdMaxDampLimitMap_0_0_to_1_0: category=ARRAY
    element Element: category=VALUE, type=Float32_0_0_to_1_0, array-size-semantics=FIXED-SIZE, max-number-of-elements=12
  4 x app type, all with category=VALUE:
    Degrees_0_0_to_50_0: compu {phys=raw for raw 0..50; unit deg}, range phys 0..50, unit=deg
    NmPerSec_50_0_to_255000_0: compu {phys=raw for raw 50..255000; unit Nm/s}, range phys 50..255000, unit=Nm/s  # Rate of change of torque
    RevsPerSec_0_0_to_8_0: compu {phys=raw for raw 0..8; unit revs/S}, range phys 0..8, unit=revs/S
    Degrees_0_0_to_127_0: compu {phys=raw for raw 0..127; unit deg}, range phys 0..127, unit=deg
  application array data type tResPosBpts_0_0_to_127_0: category=ARRAY
    element Element: category=VALUE, type=Degrees_0_0_to_127_0, array-size-semantics=FIXED-SIZE, max-number-of-elements=5
  application array data type tResDmpgMap_0_0_to_1_0: category=ARRAY
    element Element: category=VALUE, type=Percent_0_0_to_1_0, array-size-semantics=FIXED-SIZE, max-number-of-elements=5
package /DataTypeMappingSets
  data type mapping set MappingSet
    data-type-maps:
      application-data-type=Float32, implementation-data-type=Float32
      application-data-type=Nm_n255_0_to_255_0, implementation-data-type=Nm
      application-data-type=tQualityFactor, implementation-data-type=tQualityFactor
      application-data-type=Nm, implementation-data-type=Nm
      application-data-type=tAssistTorque, implementation-data-type=tAssistTorque
      application-data-type=NmPerSec, implementation-data-type=NmPerSec
      application-data-type=tInputTorque, implementation-data-type=tInputTorque
      application-data-type=Degrees_n720_0_to_720_0, implementation-data-type=Degrees
      application-data-type=Boolean, implementation-data-type=Boolean
      application-data-type=tExtendedQf, implementation-data-type=tExtendedQf
      application-data-type=Degrees, implementation-data-type=Degrees
      application-data-type=tColumnPosition, implementation-data-type=tColumnPosition
      application-data-type=RevsPerSec, implementation-data-type=RevsPerSec
      application-data-type=tColumnVelocity, implementation-data-type=tColumnVelocity
      application-data-type=mm, implementation-data-type=mm
      application-data-type=Kph_0_to_400, implementation-data-type=Kph
      application-data-type=Kph, implementation-data-type=Kph
      application-data-type=tVehicleSpd, implementation-data-type=tVehicleSpd
      application-data-type=Percent, implementation-data-type=Percent
      application-data-type=tEstimatedSteeringPosition, implementation-data-type=tEstimatedSteeringPosition
      application-data-type=DegreesPerSec, implementation-data-type=DegreesPerSec
      application-data-type=tYawRateData, implementation-data-type=tYawRateData
      application-data-type=Float32_0_0_to_255_0, implementation-data-type=Float32
      application-data-type=tVspdBkpts_0_0_to_255_0, implementation-data-type=tVspdBkpts
      application-data-type=UInt8_1_to_10, implementation-data-type=UInt8
      application-data-type=tStraightAheadOffset, implementation-data-type=tStraightAheadOffset
      application-data-type=tArbitrationState, implementation-data-type=tArbitrationState
      application-data-type=tResPosnInUse, implementation-data-type=tResPosnInUse
      application-data-type=Degrees_0_0_to_720_0, implementation-data-type=Degrees
      application-data-type=tResPositionLimitsNvmData, implementation-data-type=tResPositionLimitsNvmData
      application-data-type=tResStraightAheadOffsetNvmData, implementation-data-type=tResStraightAheadOffsetNvmData
      application-data-type=UInt8, implementation-data-type=UInt8
      application-data-type=Degrees_0_0_to_63_0, implementation-data-type=Degrees
      application-data-type=Kph_0_0_to_255_0, implementation-data-type=Kph
      application-data-type=tResVspdBkpts_0_0_to_255_0, implementation-data-type=tResVspdBkpts
      application-data-type=Degrees_1_0_to_127_0, implementation-data-type=Degrees
      application-data-type=tResDegreesMap_1_0_to_127_0, implementation-data-type=tResDegreesMap
      application-data-type=Percent_0_0_to_1_0, implementation-data-type=Percent
      application-data-type=tResPercentMap_0_0_to_1_0, implementation-data-type=tResPercentMap
      application-data-type=DegreesPerSec_2_5_to_8_0, implementation-data-type=DegreesPerSec
      application-data-type=tHvdDeadBandLimitMap_2_5_to_8_0, implementation-data-type=tHvdDeadBandLimitMap
      application-data-type=DegreesPerSec_1_0_0_to_2_0, implementation-data-type=DegreesPerSec_1
      application-data-type=DegreesPerSec_1, implementation-data-type=DegreesPerSec_1
      application-data-type=tHvdLinearFactorMap_0_0_to_2_0, implementation-data-type=tHvdLinearFactorMap
      application-data-type=Float32_0_0_to_1_0, implementation-data-type=Float32
      application-data-type=tHvdMaxDampLimitMap_0_0_to_1_0, implementation-data-type=tHvdMaxDampLimitMap
      application-data-type=Degrees_0_0_to_50_0, implementation-data-type=Degrees
      application-data-type=NmPerSec_50_0_to_255000_0, implementation-data-type=NmPerSec
      application-data-type=RevsPerSec_0_0_to_8_0, implementation-data-type=RevsPerSec
      application-data-type=Degrees_0_0_to_127_0, implementation-data-type=Degrees
      application-data-type=tResPosBpts_0_0_to_127_0, implementation-data-type=tResPosBpts
      application-data-type=tResDmpgMap_0_0_to_1_0, implementation-data-type=tResDmpgMap
package /SwAddrMethods
  7 x sw addr method, all with memory-allocation-keyword-policy=ADDR-METHOD-SHORT-NAME, section-type=CALIBRATION-ONLINE:
    VehicleTune
    PlatformTune
    DevelopmentTune
    SteeringTune
    SensorTune
    EppTune
    GearTune
package /Predefined_DEV/ImplementationDataTypes
  impl type NvM_RequestResultType: compu {0=NVM_REQ_OK, 1=NVM_REQ_NOT_OK, 2=NVM_REQ_PENDING, 3=NVM_REQ_INTEGRITY_FAILED, 4=NVM_REQ_BLOCK_SKIPPED, 5=NVM_REQ_NV_INVALIDATED, 6=NVM_REQ_CANCELED, 7=NVM_REQ_REDUNDANCY_FAILED, 8=NVM_REQ_RESTORED_FROM_ROM}, implementation-data-type=uint8
package /Predefined_DEV/PortInterfaces
  client server interface NvMService_AC2_SRBS: is-service=true
    operation GetErrorStatus: possible-error=NvMService_AC2_SRBS/E_NOT_OK
      arg ErrorStatus: type=NvM_RequestResultType, direction=OUT, server-argument-impl-policy=USE-ARGUMENT-TYPE
    operation SetRamBlockStatus: possible-error=NvMService_AC2_SRBS/E_NOT_OK
      arg RamBlockStatus: type=boolean, direction=IN, server-argument-impl-policy=USE-ARGUMENT-TYPE
    error E_NOT_OK: error-code=1
package /MICROSAR/Dem_swc/DataTypes
  18 x impl type:
    Dem_EventIdType: range raw 1..65535, implementation-data-type=uint16
    Dem_RatioIdType: range raw 1..65535, implementation-data-type=uint16
    Dem_DTCStatusMaskType: range raw 0..255, implementation-data-type=uint8
    Dem_OperationCycleIdType: range raw 0..255, implementation-data-type=uint8
    Dem_DTCGroupType: range raw 0..16777215, implementation-data-type=uint32
    Dem_MaxDataValueType: category=ARRAY, sw-calibration-access=READ-ONLY
      element Dem_MaxDataValueTypeElement: array-size=1, array-size-semantics=FIXED-SIZE, implementation-data-type=uint8
    Dem_EventStatusType: compu {0=DEM_EVENT_STATUS_PASSED, 1=DEM_EVENT_STATUS_FAILED, 2=DEM_EVENT_STATUS_PREPASSED, 3=DEM_EVENT_STATUS_PREFAILED}, implementation-data-type=uint8
    Dem_EventStatusExtendedType: compu {1=DEM_UDS_STATUS_TF, 2=DEM_UDS_STATUS_TFTOC, 4=DEM_UDS_STATUS_PDTC, 8=DEM_UDS_STATUS_CDTC, 16=DEM_UDS_STATUS_TNCSLC, 32=DEM_UDS_STATUS_TFSLC, 64=DEM_UDS_STATUS_TNCTOC, 128=DEM_UDS_STATUS_WIR}, implementation-data-type=uint8
    Dem_InitMonitorReasonType: compu {1=DEM_INIT_MONITOR_CLEAR, 2=DEM_INIT_MONITOR_RESTART, 3=DEM_INIT_MONITOR_REENABLED, 4=DEM_INIT_MONITOR_STORAGE_REENABLED}, implementation-data-type=uint8
    Dem_DTCOriginType: compu {1=DEM_DTC_ORIGIN_PRIMARY_MEMORY, 2=DEM_DTC_ORIGIN_MIRROR_MEMORY, 3=DEM_DTC_ORIGIN_PERMANENT_MEMORY, 4=DEM_DTC_ORIGIN_SECONDARY_MEMORY, 4=DEM_DTC_ORIGIN_USERDEFINED_MEMORY_10, 4=DEM_DTC_ORIGIN_USERDEFINED_MEMORY_11, 4=DEM_DTC_ORIGIN_USERDEFINED_MEMORY_12, 4=DEM_DTC_ORIGIN_USERDEFINED_MEMORY_13, 4=DEM_DTC_ORIGIN_USERDEFINED_MEMORY_14, 4=DEM_DTC_ORIGIN_USERDEFINED_MEMORY_15, 4=DEM_DTC_ORIGIN_USERDEFINED_MEMORY_16, 4=DEM_DTC_ORIGIN_USERDEFINED_MEMORY_17, 4=DEM_DTC_ORIGIN_USERDEFINED_MEMORY_18, 4=DEM_DTC_ORIGIN_USERDEFINED_MEMORY_19, 4=DEM_DTC_ORIGIN_USERDEFINED_MEMORY_1A, 4=DEM_DTC_ORIGIN_USERDEFINED_MEMORY_1B, 4=DEM_DTC_ORIGIN_USERDEFINED_MEMORY_1C, 4=DEM_DTC_ORIGIN_USERDEFINED_MEMORY_1D, 4=DEM_DTC_ORIGIN_USERDEFINED_MEMORY_1E, 4=DEM_DTC_ORIGIN_USERDEFINED_MEMORY_1F, 4=DEM_DTC_ORIGIN_USERDEFINED_MEMORY_20, 4=DEM_DTC_ORIGIN_USERDEFINED_MEMORY_21, 4=DEM_DTC_ORIGIN_USERDEFINED_MEMORY_22, 4=DEM_DTC_ORIGIN_USERDEFINED_MEMORY_23, 4=DEM_DTC_ORIGIN_USERDEFINED_MEMORY_24, 4=DEM_DTC_ORIGIN_USERDEFINED_MEMORY_25, 4=DEM_DTC_ORIGIN_USERDEFINED_MEMORY_26, 4=DEM_DTC_ORIGIN_USERDEFINED_MEMORY_27, 4=DEM_DTC_ORIGIN_USERDEFINED_MEMORY_28, 4=DEM_DTC_ORIGIN_USERDEFINED_MEMORY_29, 4=DEM_DTC_ORIGIN_USERDEFINED_MEMORY_2A, 4=DEM_DTC_ORIGIN_USERDEFINED_MEMORY_2B, 4=DEM_DTC_ORIGIN_USERDEFINED_MEMORY_2C, 4=DEM_DTC_ORIGIN_USERDEFINED_MEMORY_2D, 4=DEM_DTC_ORIGIN_USERDEFINED_MEMORY_2E, 4=DEM_DTC_ORIGIN_USERDEFINED_MEMORY_2F, 4=DEM_DTC_ORIGIN_USERDEFINED_MEMORY_30, 4=DEM_DTC_ORIGIN_USERDEFINED_MEMORY_31, 4=DEM_DTC_ORIGIN_USERDEFINED_MEMORY_32, 4=DEM_DTC_ORIGIN_USERDEFINED_MEMORY_33, 4=DEM_DTC_ORIGIN_USERDEFINED_MEMORY_34, 4=DEM_DTC_ORIGIN_USERDEFINED_MEMORY_35, 4=DEM_DTC_ORIGIN_USERDEFINED_MEMORY_36, 4=DEM_DTC_ORIGIN_USERDEFINED_MEMORY_37, 4=DEM_DTC_ORIGIN_USERDEFINED_MEMORY_38, 4=DEM_DTC_ORIGIN_USERDEFINED_MEMORY_39, 4=DEM_DTC_ORIGIN_USERDEFINED_MEMORY_3A, 4=DEM_DTC_ORIGIN_USERDEFINED_MEMORY_3B, 4=DEM_DTC_ORIGIN_USERDEFINED_MEMORY_3C, 4=DEM_DTC_ORIGIN_USERDEFINED_MEMORY_3D, 4=DEM_DTC_ORIGIN_USERDEFINED_MEMORY_3E, 4=DEM_DTC_ORIGIN_USERDEFINED_MEMORY_3F, 4=DEM_DTC_ORIGIN_USERDEFINED_MEMORY_40, 4=DEM_DTC_ORIGIN_USERDEFINED_MEMORY_41, 4=DEM_DTC_ORIGIN_USERDEFINED_MEMORY_42, 4=DEM_DTC_ORIGIN_USERDEFINED_MEMORY_43, 4=DEM_DTC_ORIGIN_USERDEFINED_MEMORY_44, 4=DEM_DTC_ORIGIN_USERDEFINED_MEMORY_45, 4=DEM_DTC_ORIGIN_USERDEFINED_MEMORY_46, 4=DEM_DTC_ORIGIN_USERDEFINED_MEMORY_47, 4=DEM_DTC_ORIGIN_USERDEFINED_MEMORY_48, 4=DEM_DTC_ORIGIN_USERDEFINED_MEMORY_49, 4=DEM_DTC_ORIGIN_USERDEFINED_MEMORY_4A, 4=DEM_DTC_ORIGIN_USERDEFINED_MEMORY_4B, 4=DEM_DTC_ORIGIN_USERDEFINED_MEMORY_4C, 4=DEM_DTC_ORIGIN_USERDEFINED_MEMORY_4D, 4=DEM_DTC_ORIGIN_USERDEFINED_MEMORY_4E, 4=DEM_DTC_ORIGIN_USERDEFINED_MEMORY_4F, 4=DEM_DTC_ORIGIN_USERDEFINED_MEMORY_50, 4=DEM_DTC_ORIGIN_USERDEFINED_MEMORY_51, 4=DEM_DTC_ORIGIN_USERDEFINED_MEMORY_52, 4=DEM_DTC_ORIGIN_USERDEFINED_MEMORY_53, 4=DEM_DTC_ORIGIN_USERDEFINED_MEMORY_54, 4=DEM_DTC_ORIGIN_USERDEFINED_MEMORY_55, 4=DEM_DTC_ORIGIN_USERDEFINED_MEMORY_56, 4=DEM_DTC_ORIGIN_USERDEFINED_MEMORY_57, 4=DEM_DTC_ORIGIN_USERDEFINED_MEMORY_58, 4=DEM_DTC_ORIGIN_USERDEFINED_MEMORY_59, 4=DEM_DTC_ORIGIN_USERDEFINED_MEMORY_5A, 4=DEM_DTC_ORIGIN_USERDEFINED_MEMORY_5B, 4=DEM_DTC_ORIGIN_USERDEFINED_MEMORY_5C, 4=DEM_DTC_ORIGIN_USERDEFINED_MEMORY_5D, 4=DEM_DTC_ORIGIN_USERDEFINED_MEMORY_5E, 4=DEM_DTC_ORIGIN_USERDEFINED_MEMORY_5F, 4=DEM_DTC_ORIGIN_USERDEFINED_MEMORY_60, 4=DEM_DTC_ORIGIN_USERDEFINED_MEMORY_61, 4=DEM_DTC_ORIGIN_USERDEFINED_MEMORY_62, 4=DEM_DTC_ORIGIN_USERDEFINED_MEMORY_63, 4=DEM_DTC_ORIGIN_USERDEFINED_MEMORY_64, 4=DEM_DTC_ORIGIN_USERDEFINED_MEMORY_65, 4=DEM_DTC_ORIGIN_USERDEFINED_MEMORY_66, 4=DEM_DTC_ORIGIN_USERDEFINED_MEMORY_67, 4=DEM_DTC_ORIGIN_USERDEFINED_MEMORY_68, 4=DEM_DTC_ORIGIN_USERDEFINED_MEMORY_69, 4=DEM_DTC_ORIGIN_USERDEFINED_MEMORY_6A, 4=DEM_DTC_ORIGIN_USERDEFINED_MEMORY_6B, 4=DEM_DTC_ORIGIN_USERDEFINED_MEMORY_6C, 4=DEM_DTC_ORIGIN_USERDEFINED_MEMORY_6D, 4=DEM_DTC_ORIGIN_USERDEFINED_MEMORY_6E, 4=DEM_DTC_ORIGIN_USERDEFINED_MEMORY_6F, 4=DEM_DTC_ORIGIN_USERDEFINED_MEMORY_70, 4=DEM_DTC_ORIGIN_USERDEFINED_MEMORY_71, 4=DEM_DTC_ORIGIN_USERDEFINED_MEMORY_72, 4=DEM_DTC_ORIGIN_USERDEFINED_MEMORY_73, 4=DEM_DTC_ORIGIN_USERDEFINED_MEMORY_74, 4=DEM_DTC_ORIGIN_USERDEFINED_MEMORY_75, 4=DEM_DTC_ORIGIN_USERDEFINED_MEMORY_76, 4=DEM_DTC_ORIGIN_USERDEFINED_MEMORY_77, 4=DEM_DTC_ORIGIN_USERDEFINED_MEMORY_78, 4=DEM_DTC_ORIGIN_USERDEFINED_MEMORY_79, 4=DEM_DTC_ORIGIN_USERDEFINED_MEMORY_7A, 4=DEM_DTC_ORIGIN_USERDEFINED_MEMORY_7B, 4=DEM_DTC_ORIGIN_USERDEFINED_MEMORY_7C, 4=DEM_DTC_ORIGIN_USERDEFINED_MEMORY_7D, 4=DEM_DTC_ORIGIN_USERDEFINED_MEMORY_7E, 4=DEM_DTC_ORIGIN_USERDEFINED_MEMORY_7F, 4=DEM_DTC_ORIGIN_USERDEFINED_MEMORY_80, 4=DEM_DTC_ORIGIN_USERDEFINED_MEMORY_81, 4=DEM_DTC_ORIGIN_USERDEFINED_MEMORY_82, 4=DEM_DTC_ORIGIN_USERDEFINED_MEMORY_83, 4=DEM_DTC_ORIGIN_USERDEFINED_MEMORY_84, 4=DEM_DTC_ORIGIN_USERDEFINED_MEMORY_85, 4=DEM_DTC_ORIGIN_USERDEFINED_MEMORY_86, 4=DEM_DTC_ORIGIN_USERDEFINED_MEMORY_87, 4=DEM_DTC_ORIGIN_USERDEFINED_MEMORY_88, 4=DEM_DTC_ORIGIN_USERDEFINED_MEMORY_89, 4=DEM_DTC_ORIGIN_USERDEFINED_MEMORY_8A, 4=DEM_DTC_ORIGIN_USERDEFINED_MEMORY_8B, 4=DEM_DTC_ORIGIN_USERDEFINED_MEMORY_8C, 4=DEM_DTC_ORIGIN_USERDEFINED_MEMORY_8D, 4=DEM_DTC_ORIGIN_USERDEFINED_MEMORY_8E, 4=DEM_DTC_ORIGIN_USERDEFINED_MEMORY_8F, 4=DEM_DTC_ORIGIN_USERDEFINED_MEMORY_90, 4=DEM_DTC_ORIGIN_USERDEFINED_MEMORY_91, 4=DEM_DTC_ORIGIN_USERDEFINED_MEMORY_92, 4=DEM_DTC_ORIGIN_USERDEFINED_MEMORY_93, 4=DEM_DTC_ORIGIN_USERDEFINED_MEMORY_94, 4=DEM_DTC_ORIGIN_USERDEFINED_MEMORY_95, 4=DEM_DTC_ORIGIN_USERDEFINED_MEMORY_96, 4=DEM_DTC_ORIGIN_USERDEFINED_MEMORY_97, 4=DEM_DTC_ORIGIN_USERDEFINED_MEMORY_98, 4=DEM_DTC_ORIGIN_USERDEFINED_MEMORY_99, 4=DEM_DTC_ORIGIN_USERDEFINED_MEMORY_9A, 4=DEM_DTC_ORIGIN_USERDEFINED_MEMORY_9B, 4=DEM_DTC_ORIGIN_USERDEFINED_MEMORY_9C, 4=DEM_DTC_ORIGIN_USERDEFINED_MEMORY_9D, 4=DEM_DTC_ORIGIN_USERDEFINED_MEMORY_9E, 4=DEM_DTC_ORIGIN_USERDEFINED_MEMORY_9F, 4=DEM_DTC_ORIGIN_USERDEFINED_MEMORY_A0, 4=DEM_DTC_ORIGIN_USERDEFINED_MEMORY_A1, 4=DEM_DTC_ORIGIN_USERDEFINED_MEMORY_A2, 4=DEM_DTC_ORIGIN_USERDEFINED_MEMORY_A3, 4=DEM_DTC_ORIGIN_USERDEFINED_MEMORY_A4, 4=DEM_DTC_ORIGIN_USERDEFINED_MEMORY_A5, 4=DEM_DTC_ORIGIN_USERDEFINED_MEMORY_A6, 4=DEM_DTC_ORIGIN_USERDEFINED_MEMORY_A7, 4=DEM_DTC_ORIGIN_USERDEFINED_MEMORY_A8, 4=DEM_DTC_ORIGIN_USERDEFINED_MEMORY_A9, 4=DEM_DTC_ORIGIN_USERDEFINED_MEMORY_AA, 4=DEM_DTC_ORIGIN_USERDEFINED_MEMORY_AB, 4=DEM_DTC_ORIGIN_USERDEFINED_MEMORY_AC, 4=DEM_DTC_ORIGIN_USERDEFINED_MEMORY_AD, 4=DEM_DTC_ORIGIN_USERDEFINED_MEMORY_AE, 4=DEM_DTC_ORIGIN_USERDEFINED_MEMORY_AF, 4=DEM_DTC_ORIGIN_USERDEFINED_MEMORY_B0, 4=DEM_DTC_ORIGIN_USERDEFINED_MEMORY_B1, 4=DEM_DTC_ORIGIN_USERDEFINED_MEMORY_B2, 4=DEM_DTC_ORIGIN_USERDEFINED_MEMORY_B3, 4=DEM_DTC_ORIGIN_USERDEFINED_MEMORY_B4, 4=DEM_DTC_ORIGIN_USERDEFINED_MEMORY_B5, 4=DEM_DTC_ORIGIN_USERDEFINED_MEMORY_B6, 4=DEM_DTC_ORIGIN_USERDEFINED_MEMORY_B7, 4=DEM_DTC_ORIGIN_USERDEFINED_MEMORY_B8, 4=DEM_DTC_ORIGIN_USERDEFINED_MEMORY_B9, 4=DEM_DTC_ORIGIN_USERDEFINED_MEMORY_BA, 4=DEM_DTC_ORIGIN_USERDEFINED_MEMORY_BB, 4=DEM_DTC_ORIGIN_USERDEFINED_MEMORY_BC, 4=DEM_DTC_ORIGIN_USERDEFINED_MEMORY_BD, 4=DEM_DTC_ORIGIN_USERDEFINED_MEMORY_BE, 4=DEM_DTC_ORIGIN_USERDEFINED_MEMORY_BF, 4=DEM_DTC_ORIGIN_USERDEFINED_MEMORY_C0, 4=DEM_DTC_ORIGIN_USERDEFINED_MEMORY_C1, 4=DEM_DTC_ORIGIN_USERDEFINED_MEMORY_C2, 4=DEM_DTC_ORIGIN_USERDEFINED_MEMORY_C3, 4=DEM_DTC_ORIGIN_USERDEFINED_MEMORY_C4, 4=DEM_DTC_ORIGIN_USERDEFINED_MEMORY_C5, 4=DEM_DTC_ORIGIN_USERDEFINED_MEMORY_C6, 4=DEM_DTC_ORIGIN_USERDEFINED_MEMORY_C7, 4=DEM_DTC_ORIGIN_USERDEFINED_MEMORY_C8, 4=DEM_DTC_ORIGIN_USERDEFINED_MEMORY_C9, 4=DEM_DTC_ORIGIN_USERDEFINED_MEMORY_CA, 4=DEM_DTC_ORIGIN_USERDEFINED_MEMORY_CB, 4=DEM_DTC_ORIGIN_USERDEFINED_MEMORY_CC, 4=DEM_DTC_ORIGIN_USERDEFINED_MEMORY_CD, 4=DEM_DTC_ORIGIN_USERDEFINED_MEMORY_CE, 4=DEM_DTC_ORIGIN_USERDEFINED_MEMORY_CF, 4=DEM_DTC_ORIGIN_USERDEFINED_MEMORY_D0, 4=DEM_DTC_ORIGIN_USERDEFINED_MEMORY_D1, 4=DEM_DTC_ORIGIN_USERDEFINED_MEMORY_D2, 4=DEM_DTC_ORIGIN_USERDEFINED_MEMORY_D3, 4=DEM_DTC_ORIGIN_USERDEFINED_MEMORY_D4, 4=DEM_DTC_ORIGIN_USERDEFINED_MEMORY_D5, 4=DEM_DTC_ORIGIN_USERDEFINED_MEMORY_D6, 4=DEM_DTC_ORIGIN_USERDEFINED_MEMORY_D7, 4=DEM_DTC_ORIGIN_USERDEFINED_MEMORY_D8, 4=DEM_DTC_ORIGIN_USERDEFINED_MEMORY_D9, 4=DEM_DTC_ORIGIN_USERDEFINED_MEMORY_DA, 4=DEM_DTC_ORIGIN_USERDEFINED_MEMORY_DB, 4=DEM_DTC_ORIGIN_USERDEFINED_MEMORY_DC, 4=DEM_DTC_ORIGIN_USERDEFINED_MEMORY_DD, 4=DEM_DTC_ORIGIN_USERDEFINED_MEMORY_DE, 4=DEM_DTC_ORIGIN_USERDEFINED_MEMORY_DF, 4=DEM_DTC_ORIGIN_USERDEFINED_MEMORY_E0, 4=DEM_DTC_ORIGIN_USERDEFINED_MEMORY_E1, 4=DEM_DTC_ORIGIN_USERDEFINED_MEMORY_E2, 4=DEM_DTC_ORIGIN_USERDEFINED_MEMORY_E3, 4=DEM_DTC_ORIGIN_USERDEFINED_MEMORY_E4, 4=DEM_DTC_ORIGIN_USERDEFINED_MEMORY_E5, 4=DEM_DTC_ORIGIN_USERDEFINED_MEMORY_E6, 4=DEM_DTC_ORIGIN_USERDEFINED_MEMORY_E7, 4=DEM_DTC_ORIGIN_USERDEFINED_MEMORY_E8, 4=DEM_DTC_ORIGIN_USERDEFINED_MEMORY_E9, 4=DEM_DTC_ORIGIN_USERDEFINED_MEMORY_EA, 4=DEM_DTC_ORIGIN_USERDEFINED_MEMORY_EB, 4=DEM_DTC_ORIGIN_USERDEFINED_MEMORY_EC, 4=DEM_DTC_ORIGIN_USERDEFINED_MEMORY_ED, 4=DEM_DTC_ORIGIN_USERDEFINED_MEMORY_EE, 4=DEM_DTC_ORIGIN_USERDEFINED_MEMORY_EF, 4=DEM_DTC_ORIGIN_USERDEFINED_MEMORY_F0, 4=DEM_DTC_ORIGIN_USERDEFINED_MEMORY_F1, 4=DEM_DTC_ORIGIN_USERDEFINED_MEMORY_F2, 4=DEM_DTC_ORIGIN_USERDEFINED_MEMORY_F3, 4=DEM_DTC_ORIGIN_USERDEFINED_MEMORY_F4, 4=DEM_DTC_ORIGIN_USERDEFINED_MEMORY_F5, 4=DEM_DTC_ORIGIN_USERDEFINED_MEMORY_F6, 4=DEM_DTC_ORIGIN_USERDEFINED_MEMORY_F7, 4=DEM_DTC_ORIGIN_USERDEFINED_MEMORY_F8, 4=DEM_DTC_ORIGIN_USERDEFINED_MEMORY_F9, 4=DEM_DTC_ORIGIN_USERDEFINED_MEMORY_FA, 4=DEM_DTC_ORIGIN_USERDEFINED_MEMORY_FB, 4=DEM_DTC_ORIGIN_USERDEFINED_MEMORY_FC, 4=DEM_DTC_ORIGIN_USERDEFINED_MEMORY_FD, 4=DEM_DTC_ORIGIN_USERDEFINED_MEMORY_FE, 4=DEM_DTC_ORIGIN_USERDEFINED_MEMORY_FF}, implementation-data-type=uint8
    Dem_DTCFormatType: compu {0=DEM_DTC_FORMAT_OBD, 1=DEM_DTC_FORMAT_UDS, 2=DEM_DTC_FORMAT_J1939}, implementation-data-type=uint8
    Dem_OperationCycleStateType: compu {0=DEM_CYCLE_STATE_START, 1=DEM_CYCLE_STATE_END}, implementation-data-type=uint8
    Dem_IndicatorStatusType: compu {0=DEM_INDICATOR_OFF, 1=DEM_INDICATOR_CONTINUOUS, 2=DEM_INDICATOR_BLINKING, 3=DEM_INDICATOR_BLINK_CONT, 4=DEM_INDICATOR_SLOW_FLASH, 5=DEM_INDICATOR_FAST_FLASH, 6=DEM_INDICATOR_ON_DEMAND, 7=DEM_INDICATOR_SHORT}, implementation-data-type=uint8
    Dem_DTCKindType: compu {1=DEM_DTC_KIND_ALL_DTCS, 2=DEM_DTC_KIND_EMISSION_REL_DTCS}, implementation-data-type=uint8
    Dem_IumprDenomCondIdType: compu {1=DEM_IUMPR_GENERAL_DENOMINATOR, 2=DEM_IUMPR_DEN_COND_COLDSTART, 3=DEM_IUMPR_DEN_COND_EVAP, 4=DEM_IUMPR_DEN_COND_500MI}, implementation-data-type=uint8
    Dem_IumprDenomCondStatusType: compu {0=DEM_IUMPR_DEN_STATUS_NOT_REACHED, 1=DEM_IUMPR_DEN_STATUS_REACHED, 2=DEM_IUMPR_DEN_STATUS_INHIBITED}, implementation-data-type=uint8
    Dem_DebounceResetStatusType: compu {0=DEM_DEBOUNCE_STATUS_FREEZE, 1=DEM_DEBOUNCE_STATUS_RESET}, implementation-data-type=uint8
    Dem_DebouncingStateType: compu {1=DEM_TEMPORARILY_DEFECTIVE, 2=DEM_FINALLY_DEFECTIVE, 4=DEM_TEMPORARILY_HEALED, 8=DEM_TEST_COMPLETE, 16=DEM_DTR_UPDATE}, implementation-data-type=uint8
package /MICROSAR/Dem_swc/Interfaces
  10 x client server interface, all with is-service=true, service-kind=DIAGNOSTIC-EVENT-MANAGER:
    CddIf
      operation ClearDTC: possible-error=[CddIf/DEM_CLEAR_WRONG_DTC, CddIf/DEM_CLEAR_WRONG_DTCORIGIN, CddIf/DEM_CLEAR_FAILED, CddIf/DEM_CLEAR_PENDING, CddIf/DEM_CLEAR_BUSY, CddIf/DEM_CLEAR_MEMORY_ERROR]
        arg DTC: type=uint32, direction=IN
        arg DTCFormat: type=Dem_DTCFormatType, direction=IN
        arg DTCOrigin: type=Dem_DTCOriginType, direction=IN
      6 x error:
        DEM_CLEAR_WRONG_DTC: error-code=1
        DEM_CLEAR_WRONG_DTCORIGIN: error-code=2
        DEM_CLEAR_FAILED: error-code=3
        DEM_CLEAR_PENDING: error-code=4
        DEM_CLEAR_BUSY: error-code=5
        DEM_CLEAR_MEMORY_ERROR: error-code=6
    DemServices
      operation GetPostRunRequested: possible-error=DemServices/E_NOT_OK
        arg IsRequested: type=boolean, direction=OUT
      operation GetDTCStatusAvailabilityMask: possible-error=DemServices/E_NOT_OK
        arg DTCStatusMask: type=uint8, direction=OUT
      error E_NOT_OK: error-code=1
    GeneralDiagnosticInfo
      9 x operation:
        GetEventStatus: possible-error=GeneralDiagnosticInfo/E_NOT_OK
          arg EventId: type=Dem_EventIdType, direction=IN
          arg EventStatusExtended: type=Dem_EventStatusExtendedType, direction=OUT
        GetEventFailed: possible-error=GeneralDiagnosticInfo/E_NOT_OK
          arg EventId: type=Dem_EventIdType, direction=IN
          arg EventFailed: type=boolean, direction=OUT
        GetEventTested: possible-error=GeneralDiagnosticInfo/E_NOT_OK
          arg EventId: type=Dem_EventIdType, direction=IN
          arg EventTested: type=boolean, direction=OUT
        GetDTCOfEvent: possible-error=[GeneralDiagnosticInfo/E_NOT_OK, GeneralDiagnosticInfo/DEM_E_NO_DTC_AVAILABLE]
          arg EventId: type=Dem_EventIdType, direction=IN
          arg DTCFormat: type=Dem_DTCFormatType, direction=IN
          arg DTCOfEvent: type=uint32, direction=OUT
        GetFaultDetectionCounter: possible-error=[GeneralDiagnosticInfo/E_NOT_OK, GeneralDiagnosticInfo/DEM_E_NO_FDC_AVAILABLE]
          arg EventId: type=Dem_EventIdType, direction=IN
          arg FaultDetectionCounter: type=sint8, direction=OUT
        GetEventFreezeFrameData: possible-error=[GeneralDiagnosticInfo/E_NOT_OK, GeneralDiagnosticInfo/DEM_E_NODATAAVAILABLE, GeneralDiagnosticInfo/DEM_E_WRONG_RECORDNUMBER, GeneralDiagnosticInfo/DEM_E_WRONG_DIDNUMBER]
          5 x arg:
            EventId: type=Dem_EventIdType, direction=IN
            RecordNumber: type=uint8, direction=IN
            ReportTotalRecord: type=boolean, direction=IN
            DataId: type=uint16, direction=IN
            DestBuffer: type=Dem_MaxDataValueType, direction=OUT
        GetEventExtendedDataRecord: possible-error=[GeneralDiagnosticInfo/E_NOT_OK, GeneralDiagnosticInfo/DEM_E_NODATAAVAILABLE, GeneralDiagnosticInfo/DEM_E_WRONG_RECORDNUMBER]
          arg EventId: type=Dem_EventIdType, direction=IN
          arg RecordNumber: type=uint8, direction=IN
          arg DestBuffer: type=Dem_MaxDataValueType, direction=OUT
        GetEventEnableCondition: possible-error=GeneralDiagnosticInfo/E_NOT_OK
          arg EventId: type=Dem_EventIdType, direction=IN
          arg ConditionFullfilled: type=boolean, direction=OUT
        GetDebouncingOfEvent: possible-error=GeneralDiagnosticInfo/E_NOT_OK
          arg EventId: type=Dem_EventIdType, direction=IN
          arg DebouncingState: type=Dem_DebouncingStateType, direction=OUT
      6 x error:
        E_NOT_OK: error-code=1
        DEM_E_NO_DTC_AVAILABLE: error-code=2
        DEM_E_NO_FDC_AVAILABLE: error-code=3
        DEM_E_NODATAAVAILABLE: error-code=48
        DEM_E_WRONG_RECORDNUMBER: error-code=49
        DEM_E_WRONG_DIDNUMBER: error-code=50
    DiagnosticInfo
      9 x operation:
        GetEventStatus: possible-error=DiagnosticInfo/E_NOT_OK
          arg EventStatusExtended: type=Dem_EventStatusExtendedType, direction=OUT
        GetEventFailed: possible-error=DiagnosticInfo/E_NOT_OK
          arg EventFailed: type=boolean, direction=OUT
        GetEventTested: possible-error=DiagnosticInfo/E_NOT_OK
          arg EventTested: type=boolean, direction=OUT
        GetDTCOfEvent: possible-error=[DiagnosticInfo/E_NOT_OK, DiagnosticInfo/DEM_E_NO_DTC_AVAILABLE]
          arg DTCFormat: type=Dem_DTCFormatType, direction=IN
          arg DTCOfEvent: type=uint32, direction=OUT
        GetFaultDetectionCounter: possible-error=[DiagnosticInfo/E_NOT_OK, DiagnosticInfo/DEM_E_NO_FDC_AVAILABLE]
          arg FaultDetectionCounter: type=sint8, direction=OUT
        GetEventFreezeFrameData: possible-error=[DiagnosticInfo/E_NOT_OK, DiagnosticInfo/DEM_E_NODATAAVAILABLE, DiagnosticInfo/DEM_E_WRONG_RECORDNUMBER, DiagnosticInfo/DEM_E_WRONG_DIDNUMBER]
          4 x arg:
            RecordNumber: type=uint8, direction=IN
            ReportTotalRecord: type=boolean, direction=IN
            DataId: type=uint16, direction=IN
            DestBuffer: type=Dem_MaxDataValueType, direction=OUT
        GetEventExtendedDataRecord: possible-error=[DiagnosticInfo/E_NOT_OK, DiagnosticInfo/DEM_E_NODATAAVAILABLE, DiagnosticInfo/DEM_E_WRONG_RECORDNUMBER]
          arg RecordNumber: type=uint8, direction=IN
          arg DestBuffer: type=Dem_MaxDataValueType, direction=OUT
        GetEventEnableCondition: possible-error=DiagnosticInfo/E_NOT_OK
          arg ConditionFullfilled: type=boolean, direction=OUT
        GetDebouncingOfEvent: possible-error=DiagnosticInfo/E_NOT_OK
          arg DebouncingState: type=Dem_DebouncingStateType, direction=OUT
      6 x error:
        E_NOT_OK: error-code=1
        DEM_E_NO_DTC_AVAILABLE: error-code=2
        DEM_E_NO_FDC_AVAILABLE: error-code=3
        DEM_E_NODATAAVAILABLE: error-code=48
        DEM_E_WRONG_RECORDNUMBER: error-code=49
        DEM_E_WRONG_DIDNUMBER: error-code=50
    DiagnosticMonitor
      10 x operation:
        SetEventStatus: possible-error=DiagnosticMonitor/E_NOT_OK
          arg EventStatus: type=Dem_EventStatusType, direction=IN
        ResetEventStatus: possible-error=DiagnosticMonitor/E_NOT_OK
        ResetEventDebounceStatus: possible-error=DiagnosticMonitor/E_NOT_OK
          arg DebounceResetStatus: type=Dem_DebounceResetStatusType, direction=IN
        GetEventStatus: possible-error=DiagnosticMonitor/E_NOT_OK
          arg EventStatusExtended: type=Dem_EventStatusExtendedType, direction=OUT
        GetEventFailed: possible-error=DiagnosticMonitor/E_NOT_OK
          arg EventFailed: type=boolean, direction=OUT
        GetEventTested: possible-error=DiagnosticMonitor/E_NOT_OK
          arg EventTested: type=boolean, direction=OUT
        GetDTCOfEvent: possible-error=[DiagnosticMonitor/E_NOT_OK, DiagnosticMonitor/DEM_E_NO_DTC_AVAILABLE]
          arg DTCFormat: type=Dem_DTCFormatType, direction=IN
          arg DTCOfEvent: type=uint32, direction=OUT
        GetFaultDetectionCounter: possible-error=[DiagnosticMonitor/E_NOT_OK, DiagnosticMonitor/DEM_E_NO_FDC_AVAILABLE]
          arg FaultDetectionCounter: type=sint8, direction=OUT
        GetEventFreezeFrameData: possible-error=[DiagnosticMonitor/E_NOT_OK, DiagnosticMonitor/DEM_E_NODATAAVAILABLE, DiagnosticMonitor/DEM_E_WRONG_RECORDNUMBER, DiagnosticMonitor/DEM_E_WRONG_DIDNUMBER]
          4 x arg:
            RecordNumber: type=uint8, direction=IN
            ReportTotalRecord: type=boolean, direction=IN
            DataId: type=uint16, direction=IN
            DestBuffer: type=Dem_MaxDataValueType, direction=OUT
        GetEventExtendedDataRecord: possible-error=[DiagnosticMonitor/E_NOT_OK, DiagnosticMonitor/DEM_E_NODATAAVAILABLE, DiagnosticMonitor/DEM_E_WRONG_RECORDNUMBER]
          arg RecordNumber: type=uint8, direction=IN
          arg DestBuffer: type=Dem_MaxDataValueType, direction=OUT
      6 x error:
        E_NOT_OK: error-code=1
        DEM_E_NO_DTC_AVAILABLE: error-code=2
        DEM_E_NO_FDC_AVAILABLE: error-code=3
        DEM_E_NODATAAVAILABLE: error-code=48
        DEM_E_WRONG_RECORDNUMBER: error-code=49
        DEM_E_WRONG_DIDNUMBER: error-code=50
    DcmIf
      5 x operation:
        DcmClearDTC: possible-error=[DcmIf/DEM_CLEAR_WRONG_DTC, DcmIf/DEM_CLEAR_WRONG_DTCORIGIN, DcmIf/DEM_CLEAR_FAILED, DcmIf/DEM_CLEAR_PENDING, DcmIf/DEM_CLEAR_BUSY, DcmIf/DEM_CLEAR_MEMORY_ERROR]
          arg DTC: type=uint32, direction=IN
          arg DTCFormat: type=Dem_DTCFormatType, direction=IN
          arg DTCOrigin: type=Dem_DTCOriginType, direction=IN
        DcmGetNextFilteredDTCAndFDC: possible-error=DEM_FILTERED_NO_MATCHING_DTC
          arg DTC: type=uint32, direction=OUT
          arg DTCFaultDetectionCounter: type=sint8, direction=OUT
        DcmEnableDTCSetting: possible-error=[DEM_CONTROL_DTC_SETTING_N_OK, DEM_CONTROL_DTC_WRONG_DTCGROUP]
          arg DTCGroup: type=Dem_DTCGroupType, direction=IN
          arg DTCKind: type=Dem_DTCKindType, direction=IN
        DcmGetFreezeFrameDataByDTC: possible-error=[DEM_GET_FFDATABYDTC_WRONG_DTC, DEM_GET_FFDATABYDTC_WRONG_DTCORIGIN, DEM_GET_FFDATABYDTC_WRONG_RECORDNUMBER, DEM_GET_FFDATABYDTC_WRONG_BUFFERSIZE, DEM_GET_FFDATABYDTC_PENDING]
          5 x arg:
            DTC: type=uint32, direction=IN
            DTCOrigin: type=Dem_DTCOriginType, direction=IN
            RecordNumber: type=uint8, direction=IN
            DestBuffer: type=uint8, direction=OUT
            BufSize: type=uint16, direction=INOUT
        DcmGetExtendedDataRecordByDTC: possible-error=[DEM_RECORD_WRONG_DTC, DEM_RECORD_WRONG_DTCORIGIN, DEM_RECORD_WRONG_NUMBER, DEM_RECORD_WRONG_BUFFERSIZE, DEM_RECORD_PENDING]
          5 x arg:
            DTC: type=uint32, direction=IN
            DTCOrigin: type=Dem_DTCOriginType, direction=IN
            ExtendedDataNumber: type=uint8, direction=IN
            DestBuffer: type=uint8, direction=OUT
            BufSize: type=uint16, direction=INOUT
      19 x error:
        DEM_CLEAR_WRONG_DTC: error-code=1
        DEM_CONTROL_DTC_SETTING_N_OK: error-code=1
        DEM_FILTERED_NO_MATCHING_DTC: error-code=1
        DEM_GET_FFDATABYDTC_WRONG_DTC: error-code=1
        DEM_RECORD_WRONG_DTC: error-code=1
        DEM_CLEAR_WRONG_DTCORIGIN: error-code=2
        DEM_CONTROL_DTC_WRONG_DTCGROUP: error-code=2
        DEM_GET_FFDATABYDTC_WRONG_DTCORIGIN: error-code=2
        DEM_RECORD_WRONG_DTCORIGIN: error-code=2
        DEM_CLEAR_FAILED: error-code=3
        DEM_GET_FFDATABYDTC_WRONG_RECORDNUMBER: error-code=3
        DEM_RECORD_WRONG_NUMBER: error-code=3
        DEM_CLEAR_PENDING: error-code=4
        DEM_GET_FFDATABYDTC_WRONG_BUFFERSIZE: error-code=4
        DEM_RECORD_WRONG_BUFFERSIZE: error-code=4
        DEM_CLEAR_BUSY: error-code=5
        DEM_GET_FFDATABYDTC_PENDING: error-code=5
        DEM_RECORD_PENDING: error-code=5
        DEM_CLEAR_MEMORY_ERROR: error-code=6
    OperationCycle
      operation SetOperationCycleState: possible-error=OperationCycle/E_NOT_OK
        arg CycleState: type=Dem_OperationCycleStateType, direction=IN
      error E_NOT_OK: error-code=1
    GeneralCallbackEventStatusChange
      operation EventStatusChanged
        arg EventId: type=Dem_EventIdType, direction=IN
        arg EventStatusOld: type=Dem_EventStatusExtendedType, direction=IN
        arg EventStatusNew: type=Dem_EventStatusExtendedType, direction=IN
    EvMemOverflowIndication
      operation GetEventMemoryOverflow: possible-error=EvMemOverflowIndication/E_NOT_OK
        arg OverflowIndication: type=boolean, direction=OUT
      operation GetNumberOfEventMemoryEntries: possible-error=EvMemOverflowIndication/E_NOT_OK
        arg NumberOfEventMemoryEntries: type=uint8, direction=OUT
      error E_NOT_OK: error-code=1
    EnableCondition
      operation SetEnableCondition: possible-error=EnableCondition/E_NOT_OK
        arg ConditionFulfilled: type=boolean, direction=IN
      error E_NOT_OK: error-code=1
